# M4KP register map
File version: 0.1
Registers are 32-bit, read-write, reset 0x0 unless marked. A register's access mark holds for its fields unless they carry their own. Offsets are from the block's base; [hi:lo] are bit positions; {n}, {i} and the like mark numbered series.

## DMA — Direct Memory Accsess Controller (DMAC)
Base 0x400A4000
0x00 STATUS ro reset 0x101F0000 — DMA Status Register
  [0] MASTER_ENABLE
0x04 CFG wo — DMA Configuration Register
  [0] MASTER_ENABLE
0x08 CTRLBASEPTR — DMA Control Data Base Pointer Register
  [31:10] CTRL_BASE_PTR
0x0C ALTCTRLBASEPTR ro — DMA Channel Alternate Control Data Base Pointer Register
  [31:0] ALT_CTRL_BASE_PTR
0x14 CHNLSWREQUEST wo — DMA Channel Software Request Register
  [31:0] CHNL_SW_REQUEST
0x18 CHNLUSEBURSTSET — DMA Channel Useburst Set Register
  [31:0] CHNL_USEBURST_SET
0x1C CHNLUSEBURSTCLR wo — DMA Channel Useburst Clear Register
  [31:0] CHNL_USEBURST_CLR
0x20 CHNLREQMASKSET — DMA Channel Request Mask Set Register
  [31:0] CHNL_REQ_MASK_SET
0x24 CHNLREQMASKCLR wo — DMA Channel Request Mask Clear Register
  [31:0] CHNL_REQ_MASK_CLR
0x28 CHNLENABLESET — DMA Channel Enable Set Register
  [31:0] CHNL_ENABLE_SET
0x2C CHNLENABLECLR wo — DMA Channel Enable Clear Register
  [31:0] CHNL_ENABLE_CLR
0x30 CHNLPRIALTSET — DMA Channel Primary-Alternate Set Register
  [31:0] CHNL_PRI_ALT_SET
0x34 CHNLPRIALTCLR wo — DMA Channel Primary-Alternate Clear Register
  [31:0] CHNL_PRI_ALT_CLR
0x38 CHNLPRIORITYSET — DMA Channel Priority Set Register
  [31:0] CHNL_PRIORITY_SET
0x3C CHNLPRIORITYCLR wo — DMA Channel Priority Clear Register
  [31:0] CHNL_PRIORITY_CLR
0x4C ERRCLR — DMA Bus Error Clear Register
  [0] ERR_CLR

## ADA — 12-bit Analog to Digital Converter(ADC)
Base 0x400BA000
Same registers: ADB 0x400BA400, ADC 0x400BA800
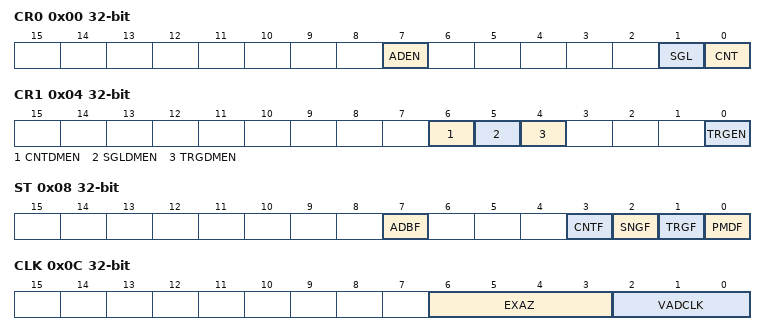
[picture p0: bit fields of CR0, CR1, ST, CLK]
0x00 CR0 — AD Control Register 0
  [7] ADEN, [1] SGL wo, [0] CNT
0x04 CR1 — AD Control Register 1
  [6] CNTDMEN, [5] SGLDMEN, [4] TRGDMEN, [0] TRGEN
0x08 ST ro — AD Status Register
  [7] ADBF, [3] CNTF, [2] SNGF, [1] TRGF, [0] PMDF
0x0C CLK — AD Conversion Clock Setting Register
  [6:3] EXAZ, [2:0] VADCLK
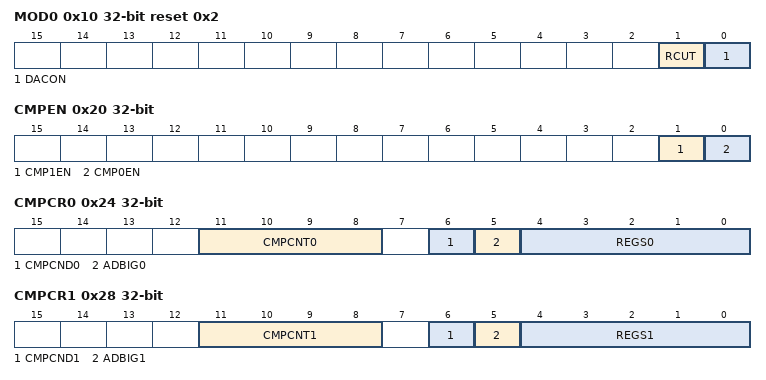
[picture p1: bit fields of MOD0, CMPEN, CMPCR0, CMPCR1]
0x10 MOD0 reset 0x2 — AD Mode Control Register 0
  [1] RCUT, [0] DACON
0x14 MOD1 reset 0x4000 — AD Mode Control Register 1
0x18 MOD2 — AD Mode Control Register 2
0x20 CMPEN — AD Monitor function interrupt permission register
  [1] CMP1EN, [0] CMP0EN
0x24 CMPCR0 — AD Monitor function Setting Register 0
  [11:8] CMPCNT0, [6] CMPCND0, [5] ADBIG0, [4:0] REGS0
0x28 CMPCR1 — AD Monitor function Setting Register 1
  [11:8] CMPCNT1, [6] CMPCND1, [5] ADBIG1, [4:0] REGS1
0x2C CMP0 — AD Conversion Result Comparison Register 0
  [15:4] AD0CMP0
0x30 CMP1 — AD Conversion Result Comparison Register 1
  [15:4] AD0CMP1
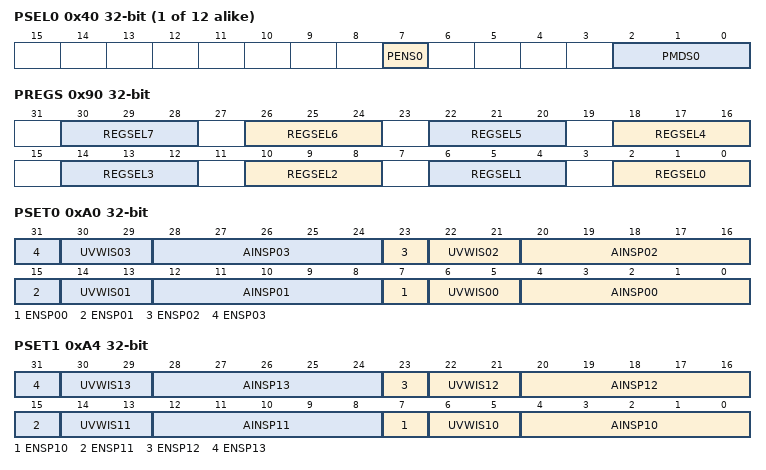
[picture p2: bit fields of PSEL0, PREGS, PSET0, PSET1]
{0x40+4i} PSEL{i} (i=0..11) — AD PMD Trigger Program Number Select Register {i}
  [7] PENS{i}, [2:0] PMDS{i}
{0x70+4i} PINTS{i} (i=0..7) — AD PMD Trigger Interrupt Select Register {i}
  [1:0] INTSEL{i}
0x90 PREGS — AD PMD Trigger Conversion Result Storage Select Register 1
  [4n+2:4n] REGSEL{n} (n=0..7)
0xA0 PSET0 — AD PMD Trigger Program Register 0
  [8n+7] ENSP{n:02} (n=0..3), [8n+6:8n+5] UVWIS{n:02} (n=0..3), [8n+4:8n] AINSP{n:02} (n=0..3)
0xA4 PSET1 — AD PMD Trigger Program Register 1
  [8n-73] ENSP{n} (n=10..13), [8n-74:8n-75] UVWIS{n} (n=10..13), [8n-76:8n-80] AINSP{n} (n=10..13)
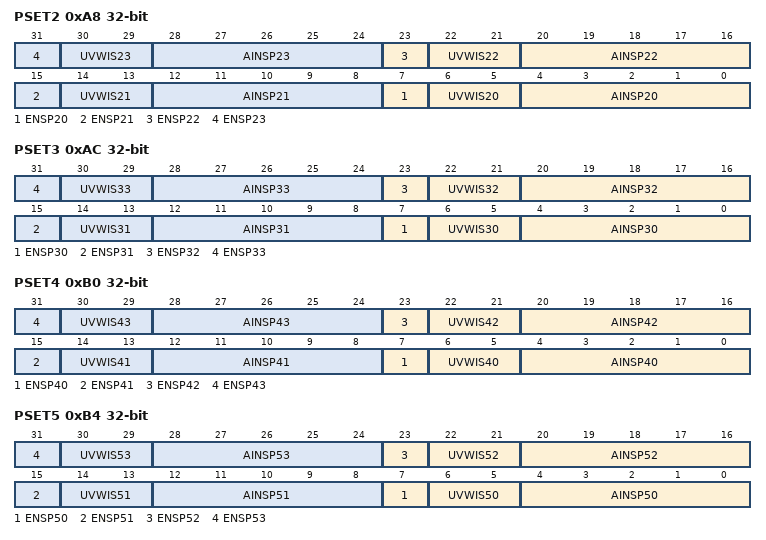
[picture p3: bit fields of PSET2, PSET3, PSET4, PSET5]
0xA8 PSET2 — AD PMD Trigger Program Register 2
  [8n-153] ENSP{n} (n=20..23), [8n-154:8n-155] UVWIS{n} (n=20..23), [8n-156:8n-160] AINSP{n} (n=20..23)
0xAC PSET3 — AD PMD Trigger Program Register 3
  [8n-233] ENSP{n} (n=30..33), [8n-234:8n-235] UVWIS{n} (n=30..33), [8n-236:8n-240] AINSP{n} (n=30..33)
0xB0 PSET4 — AD PMD Trigger Program Register 4
  [8n-313] ENSP{n} (n=40..43), [8n-314:8n-315] UVWIS{n} (n=40..43), [8n-316:8n-320] AINSP{n} (n=40..43)
0xB4 PSET5 — AD PMD Trigger Program Register 5
  [8n-393] ENSP{n} (n=50..53), [8n-394:8n-395] UVWIS{n} (n=50..53), [8n-396:8n-400] AINSP{n} (n=50..53)
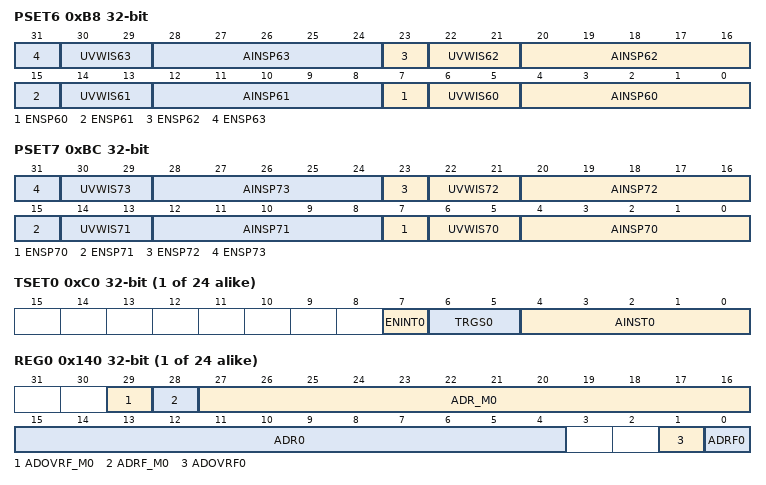
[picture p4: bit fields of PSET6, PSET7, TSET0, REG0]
0xB8 PSET6 — AD PMD Trigger Program Register 6
  [8n-473] ENSP{n} (n=60..63), [8n-474:8n-475] UVWIS{n} (n=60..63), [8n-476:8n-480] AINSP{n} (n=60..63)
0xBC PSET7 — AD PMD Trigger Program Register 7
  [8n-553] ENSP{n} (n=70..73), [8n-554:8n-555] UVWIS{n} (n=70..73), [8n-556:8n-560] AINSP{n} (n=70..73)
{0xC0+4i} TSET{i} (i=0..23) — AD General purpose Trigger Program Register {i}
  [7] ENINT{i}, [6:5] TRGS{i}, [4:0] AINST{i}
{0x140+4i} REG{i} ro (i=0..23) — AD Conversion Result Register {i}
  [29] ADOVRF_M{i}, [28] ADRF_M{i}, [27:16] ADR_M{i}, [15:4] ADR{i}, [1] ADOVRF{i}, [0] ADRF{i}
